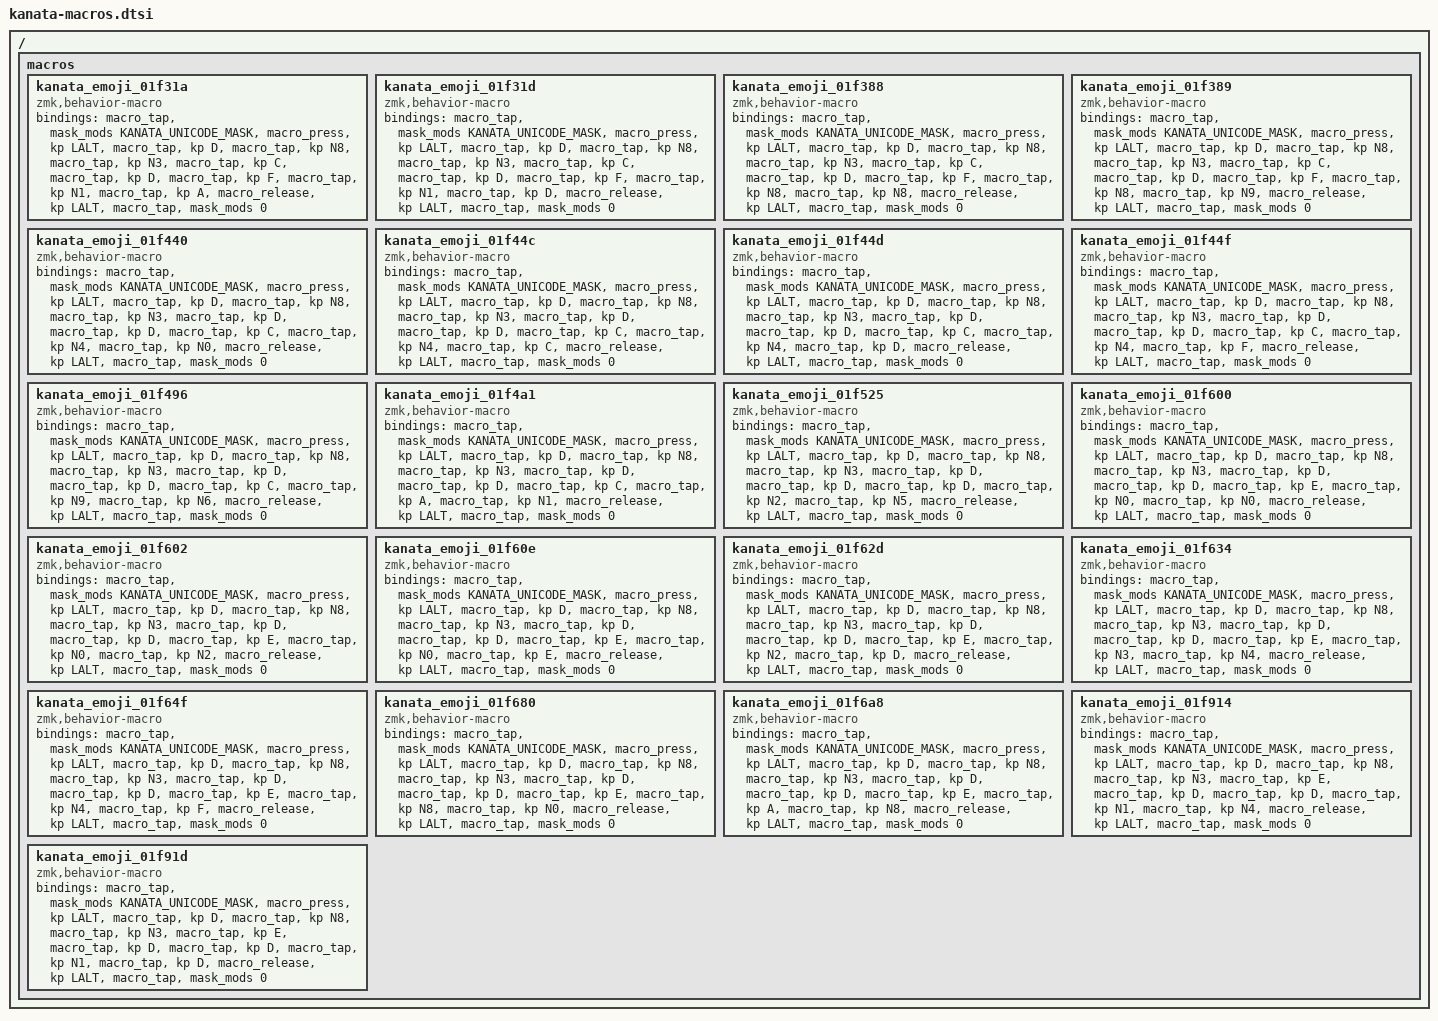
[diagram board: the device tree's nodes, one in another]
#include <dt-bindings/zmk/modifiers.h>

#define KANATA_UNICODE_MASK (MOD_LCTL | MOD_LSFT | MOD_LGUI | MOD_RCTL | MOD_RSFT | MOD_RALT | MOD_RGUI)

/ {
    macros {
        kanata_emoji_01f31a: kanata_emoji_01f31a {
            compatible = "zmk,behavior-macro";
            #binding-cells = <0>;
            bindings = <&macro_tap &mask_mods KANATA_UNICODE_MASK &macro_press &kp LALT &macro_tap &kp D &macro_tap &kp N8 &macro_tap &kp N3 &macro_tap &kp C &macro_tap &kp D &macro_tap &kp F &macro_tap &kp N1 &macro_tap &kp A &macro_release &kp LALT &macro_tap &mask_mods 0>;
        };
        kanata_emoji_01f31d: kanata_emoji_01f31d {
            compatible = "zmk,behavior-macro";
            #binding-cells = <0>;
            bindings = <&macro_tap &mask_mods KANATA_UNICODE_MASK &macro_press &kp LALT &macro_tap &kp D &macro_tap &kp N8 &macro_tap &kp N3 &macro_tap &kp C &macro_tap &kp D &macro_tap &kp F &macro_tap &kp N1 &macro_tap &kp D &macro_release &kp LALT &macro_tap &mask_mods 0>;
        };
        kanata_emoji_01f388: kanata_emoji_01f388 {
            compatible = "zmk,behavior-macro";
            #binding-cells = <0>;
            bindings = <&macro_tap &mask_mods KANATA_UNICODE_MASK &macro_press &kp LALT &macro_tap &kp D &macro_tap &kp N8 &macro_tap &kp N3 &macro_tap &kp C &macro_tap &kp D &macro_tap &kp F &macro_tap &kp N8 &macro_tap &kp N8 &macro_release &kp LALT &macro_tap &mask_mods 0>;
        };
        kanata_emoji_01f389: kanata_emoji_01f389 {
            compatible = "zmk,behavior-macro";
            #binding-cells = <0>;
            bindings = <&macro_tap &mask_mods KANATA_UNICODE_MASK &macro_press &kp LALT &macro_tap &kp D &macro_tap &kp N8 &macro_tap &kp N3 &macro_tap &kp C &macro_tap &kp D &macro_tap &kp F &macro_tap &kp N8 &macro_tap &kp N9 &macro_release &kp LALT &macro_tap &mask_mods 0>;
        };
        kanata_emoji_01f440: kanata_emoji_01f440 {
            compatible = "zmk,behavior-macro";
            #binding-cells = <0>;
            bindings = <&macro_tap &mask_mods KANATA_UNICODE_MASK &macro_press &kp LALT &macro_tap &kp D &macro_tap &kp N8 &macro_tap &kp N3 &macro_tap &kp D &macro_tap &kp D &macro_tap &kp C &macro_tap &kp N4 &macro_tap &kp N0 &macro_release &kp LALT &macro_tap &mask_mods 0>;
        };
        kanata_emoji_01f44c: kanata_emoji_01f44c {
            compatible = "zmk,behavior-macro";
            #binding-cells = <0>;
            bindings = <&macro_tap &mask_mods KANATA_UNICODE_MASK &macro_press &kp LALT &macro_tap &kp D &macro_tap &kp N8 &macro_tap &kp N3 &macro_tap &kp D &macro_tap &kp D &macro_tap &kp C &macro_tap &kp N4 &macro_tap &kp C &macro_release &kp LALT &macro_tap &mask_mods 0>;
        };
        kanata_emoji_01f44d: kanata_emoji_01f44d {
            compatible = "zmk,behavior-macro";
            #binding-cells = <0>;
            bindings = <&macro_tap &mask_mods KANATA_UNICODE_MASK &macro_press &kp LALT &macro_tap &kp D &macro_tap &kp N8 &macro_tap &kp N3 &macro_tap &kp D &macro_tap &kp D &macro_tap &kp C &macro_tap &kp N4 &macro_tap &kp D &macro_release &kp LALT &macro_tap &mask_mods 0>;
        };
        kanata_emoji_01f44f: kanata_emoji_01f44f {
            compatible = "zmk,behavior-macro";
            #binding-cells = <0>;
            bindings = <&macro_tap &mask_mods KANATA_UNICODE_MASK &macro_press &kp LALT &macro_tap &kp D &macro_tap &kp N8 &macro_tap &kp N3 &macro_tap &kp D &macro_tap &kp D &macro_tap &kp C &macro_tap &kp N4 &macro_tap &kp F &macro_release &kp LALT &macro_tap &mask_mods 0>;
        };
        kanata_emoji_01f496: kanata_emoji_01f496 {
            compatible = "zmk,behavior-macro";
            #binding-cells = <0>;
            bindings = <&macro_tap &mask_mods KANATA_UNICODE_MASK &macro_press &kp LALT &macro_tap &kp D &macro_tap &kp N8 &macro_tap &kp N3 &macro_tap &kp D &macro_tap &kp D &macro_tap &kp C &macro_tap &kp N9 &macro_tap &kp N6 &macro_release &kp LALT &macro_tap &mask_mods 0>;
        };
        kanata_emoji_01f4a1: kanata_emoji_01f4a1 {
            compatible = "zmk,behavior-macro";
            #binding-cells = <0>;
            bindings = <&macro_tap &mask_mods KANATA_UNICODE_MASK &macro_press &kp LALT &macro_tap &kp D &macro_tap &kp N8 &macro_tap &kp N3 &macro_tap &kp D &macro_tap &kp D &macro_tap &kp C &macro_tap &kp A &macro_tap &kp N1 &macro_release &kp LALT &macro_tap &mask_mods 0>;
        };
        kanata_emoji_01f525: kanata_emoji_01f525 {
            compatible = "zmk,behavior-macro";
            #binding-cells = <0>;
            bindings = <&macro_tap &mask_mods KANATA_UNICODE_MASK &macro_press &kp LALT &macro_tap &kp D &macro_tap &kp N8 &macro_tap &kp N3 &macro_tap &kp D &macro_tap &kp D &macro_tap &kp D &macro_tap &kp N2 &macro_tap &kp N5 &macro_release &kp LALT &macro_tap &mask_mods 0>;
        };
        kanata_emoji_01f600: kanata_emoji_01f600 {
            compatible = "zmk,behavior-macro";
            #binding-cells = <0>;
            bindings = <&macro_tap &mask_mods KANATA_UNICODE_MASK &macro_press &kp LALT &macro_tap &kp D &macro_tap &kp N8 &macro_tap &kp N3 &macro_tap &kp D &macro_tap &kp D &macro_tap &kp E &macro_tap &kp N0 &macro_tap &kp N0 &macro_release &kp LALT &macro_tap &mask_mods 0>;
        };
        kanata_emoji_01f602: kanata_emoji_01f602 {
            compatible = "zmk,behavior-macro";
            #binding-cells = <0>;
            bindings = <&macro_tap &mask_mods KANATA_UNICODE_MASK &macro_press &kp LALT &macro_tap &kp D &macro_tap &kp N8 &macro_tap &kp N3 &macro_tap &kp D &macro_tap &kp D &macro_tap &kp E &macro_tap &kp N0 &macro_tap &kp N2 &macro_release &kp LALT &macro_tap &mask_mods 0>;
        };
        kanata_emoji_01f60e: kanata_emoji_01f60e {
            compatible = "zmk,behavior-macro";
            #binding-cells = <0>;
            bindings = <&macro_tap &mask_mods KANATA_UNICODE_MASK &macro_press &kp LALT &macro_tap &kp D &macro_tap &kp N8 &macro_tap &kp N3 &macro_tap &kp D &macro_tap &kp D &macro_tap &kp E &macro_tap &kp N0 &macro_tap &kp E &macro_release &kp LALT &macro_tap &mask_mods 0>;
        };
        kanata_emoji_01f62d: kanata_emoji_01f62d {
            compatible = "zmk,behavior-macro";
            #binding-cells = <0>;
            bindings = <&macro_tap &mask_mods KANATA_UNICODE_MASK &macro_press &kp LALT &macro_tap &kp D &macro_tap &kp N8 &macro_tap &kp N3 &macro_tap &kp D &macro_tap &kp D &macro_tap &kp E &macro_tap &kp N2 &macro_tap &kp D &macro_release &kp LALT &macro_tap &mask_mods 0>;
        };
        kanata_emoji_01f634: kanata_emoji_01f634 {
            compatible = "zmk,behavior-macro";
            #binding-cells = <0>;
            bindings = <&macro_tap &mask_mods KANATA_UNICODE_MASK &macro_press &kp LALT &macro_tap &kp D &macro_tap &kp N8 &macro_tap &kp N3 &macro_tap &kp D &macro_tap &kp D &macro_tap &kp E &macro_tap &kp N3 &macro_tap &kp N4 &macro_release &kp LALT &macro_tap &mask_mods 0>;
        };
        kanata_emoji_01f64f: kanata_emoji_01f64f {
            compatible = "zmk,behavior-macro";
            #binding-cells = <0>;
            bindings = <&macro_tap &mask_mods KANATA_UNICODE_MASK &macro_press &kp LALT &macro_tap &kp D &macro_tap &kp N8 &macro_tap &kp N3 &macro_tap &kp D &macro_tap &kp D &macro_tap &kp E &macro_tap &kp N4 &macro_tap &kp F &macro_release &kp LALT &macro_tap &mask_mods 0>;
        };
        kanata_emoji_01f680: kanata_emoji_01f680 {
            compatible = "zmk,behavior-macro";
            #binding-cells = <0>;
            bindings = <&macro_tap &mask_mods KANATA_UNICODE_MASK &macro_press &kp LALT &macro_tap &kp D &macro_tap &kp N8 &macro_tap &kp N3 &macro_tap &kp D &macro_tap &kp D &macro_tap &kp E &macro_tap &kp N8 &macro_tap &kp N0 &macro_release &kp LALT &macro_tap &mask_mods 0>;
        };
        kanata_emoji_01f6a8: kanata_emoji_01f6a8 {
            compatible = "zmk,behavior-macro";
            #binding-cells = <0>;
            bindings = <&macro_tap &mask_mods KANATA_UNICODE_MASK &macro_press &kp LALT &macro_tap &kp D &macro_tap &kp N8 &macro_tap &kp N3 &macro_tap &kp D &macro_tap &kp D &macro_tap &kp E &macro_tap &kp A &macro_tap &kp N8 &macro_release &kp LALT &macro_tap &mask_mods 0>;
        };
        kanata_emoji_01f914: kanata_emoji_01f914 {
            compatible = "zmk,behavior-macro";
            #binding-cells = <0>;
            bindings = <&macro_tap &mask_mods KANATA_UNICODE_MASK &macro_press &kp LALT &macro_tap &kp D &macro_tap &kp N8 &macro_tap &kp N3 &macro_tap &kp E &macro_tap &kp D &macro_tap &kp D &macro_tap &kp N1 &macro_tap &kp N4 &macro_release &kp LALT &macro_tap &mask_mods 0>;
        };
        kanata_emoji_01f91d: kanata_emoji_01f91d {
            compatible = "zmk,behavior-macro";
            #binding-cells = <0>;
            bindings = <&macro_tap &mask_mods KANATA_UNICODE_MASK &macro_press &kp LALT &macro_tap &kp D &macro_tap &kp N8 &macro_tap &kp N3 &macro_tap &kp E &macro_tap &kp D &macro_tap &kp D &macro_tap &kp N1 &macro_tap &kp D &macro_release &kp LALT &macro_tap &mask_mods 0>;
        };
    };
};
